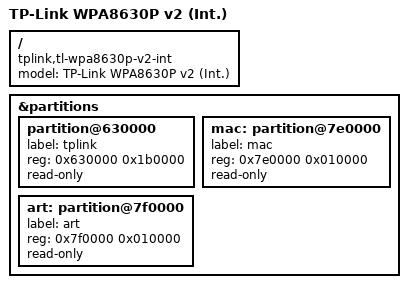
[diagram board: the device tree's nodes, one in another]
// SPDX-License-Identifier: GPL-2.0-or-later OR MIT
/dts-v1/;

#include "qca9563_tplink_tl-wpa8630p-v2.dtsi"

/ {
	compatible = "tplink,tl-wpa8630p-v2-int", "qca,qca9563";
	model = "TP-Link WPA8630P v2 (Int.)";
};

&partitions {
	partition@630000 {
		label = "tplink";
		reg = <0x630000 0x1b0000>;
		read-only;
	};

	mac: partition@7e0000 {
		label = "mac";
		reg = <0x7e0000 0x010000>;
		read-only;
	};

	art: partition@7f0000 {
		label = "art";
		reg = <0x7f0000 0x010000>;
		read-only;
	};
};
